# J7AEP_GPU_BXS464_WRAP0_GPU_SS_0_CORE_MMRS register map
Vendor: Texas Instruments
Registers are 64-bit, access per field, reset 0x0 unless marked. A register's access mark holds for its fields unless they carry their own. Offsets are as the file gives them; [hi:lo] are bit positions; 'fields as' and 'values as' point back to an identical list.

## J7AEP_GPU_BXS464_WRAP0_GPU_SS_0_CORE_MMRS (part 2 of 5)
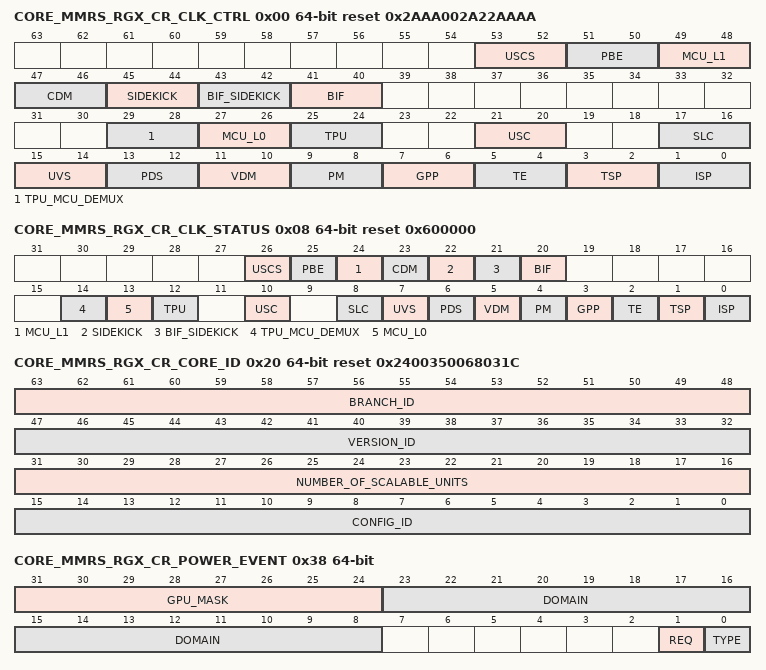
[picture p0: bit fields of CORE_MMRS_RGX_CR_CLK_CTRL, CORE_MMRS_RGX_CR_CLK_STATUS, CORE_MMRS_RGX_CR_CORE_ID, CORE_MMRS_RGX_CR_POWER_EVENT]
0x00 CORE_MMRS_RGX_CR_CLK_CTRL reset 0x2AAA002A22AAAA — Core Module Clock Control Modes. Allows individual domain clocks to be forced off, forced on or operate under automatic pipeline activity based clock gating. This register is generally controlled by the GPU firmware and should be set to AUTO. Clock gating reduces the power consumed by the device.
  [53:52] USCS rw, [51:50] PBE rw, [49:48] MCU_L1 rw, [47:46] CDM rw, [45:44] SIDEKICK rw, [43:42] BIF_SIDEKICK rw, [41:40] BIF rw, [29:28] TPU_MCU_DEMUX rw, [27:26] MCU_L0 rw, [25:24] TPU rw, [21:20] USC rw, [17:16] SLC rw, [15:14] UVS rw, [13:12] PDS rw, [11:10] VDM rw, [9:8] PM rw, [7:6] GPP rw, [5:4] TE rw, [3:2] TSP rw, [1:0] ISP rw
0x08 CORE_MMRS_RGX_CR_CLK_STATUS ro reset 0x600000 — Reports the current module clock status Clock gating state reflects the condition of the clock for each module
  [26] USCS, [25] PBE, [24] MCU_L1, [23] CDM, [22] SIDEKICK, [21] BIF_SIDEKICK, [20] BIF, [14] TPU_MCU_DEMUX, [13] MCU_L0, [12] TPU, [10] USC, [8] SLC, [7] UVS, [6] PDS, [5] VDM, [4] PM, [3] GPP, [2] TE, [1] TSP, [0] ISP
0x18 CORE_MMRS_RGX_CR_PRODUCT_ID ro reset 0x8470000 — Reports the product ID Product ID Register
  [31:16] IMG_PRODUCT_ID
0x20 CORE_MMRS_RGX_CR_CORE_ID ro reset 0x2400350068031C — Reports the product ID Core ID Register
  [63:48] BRANCH_ID — B - Branch ID
  [47:32] VERSION_ID — V - Version ID
  [31:16] NUMBER_OF_SCALABLE_UNITS — N - Number of scalable Units
  [15:0] CONFIG_ID — C - Config ID
0x28 CORE_MMRS_RGX_CR_CORE_IP_INTEGRATOR_ID ro — Reports the product ID Core IP Integrator ID Register
  [31:0] VALUE — IP company ID/Designer
0x30 CORE_MMRS_RGX_CR_CORE_IP_CHANGELIST ro — Reports the version control ID Core IP Changelist Register
  [31:0] VALUE — Version control ID
0x38 CORE_MMRS_RGX_CR_POWER_EVENT — Allows the firmware to request a power-up or power-down operation to an external (to Rogue) power-management controller When the power event operation is accepted, the firmware will either receive an RGX_CR_EVENT_STATUS_POWER_COMPLETE or RGX_CR_EVENT_STATUS_POWER_ABORT. On receipt of the reponse it will de-assert the request before issuing another request.
  [31:24] GPU_MASK rw — One bit per GPU indicating which GPUs are considered for the power event.
  [23:8] DOMAIN rw — sets which power island is enabled for the current power event request; bit0:jones, bit1-8:dusts, bit9-12:blackpearls
  [1] REQ rw — Set when a power event operation is requested
  [0] TYPE rw — The requested power event operation
0x50 CORE_MMRS_RGX_CR_DUSTS_ENABLE ro reset 0xFF — Controls how many Dual Unified Shading and Texturing Units (DUSTs) are enabled. Each DUST Contain 2 USCs and a TPU module. (Available on 2. X.X.X cores and above). Only applicable in cores with a B.V.N.C > 2.0.0.0 Controls how many Dual Unified Shading and Texturing Units (DUSTs) are enabled. Each DUST Contain 2 USCs and TPU module. Each DUST Contains 2 USCs and a TPU module. Please refer to the Customer User Guide for valid combinations. The value of this register can be overridden by the dusts_enable port at the top level. 1: DustA enabled. 3: DustB enabled. 7: DustC enabled. 15: DustD enabled
  [7:0] ENABLE — Dusts enabled
0x58 CORE_MMRS_RGX_CR_DUSTS_FUSE ro reset 0xFF — Indicates how many of the available DUST modules are enabled on the Silicon. (Available on 2.X.X.X cores and above). Shows the raw value of dusts_enable port.
  [7:0] ENABLE — Dusts enabled
0x80 CORE_MMRS_RGX_CR_CLK_XTPLUS_CTRL reset 0x800000000 — Core Module Clock Control Modes. Allows individual domain clocks to be forced off, forced on or operate under automatic pipeline activity based clock gating. This register is generally controlled by the GPU firmware and should be set to AUTO. Clock gating reduces the power consumed by the device.
  [35:34] ASTC rw
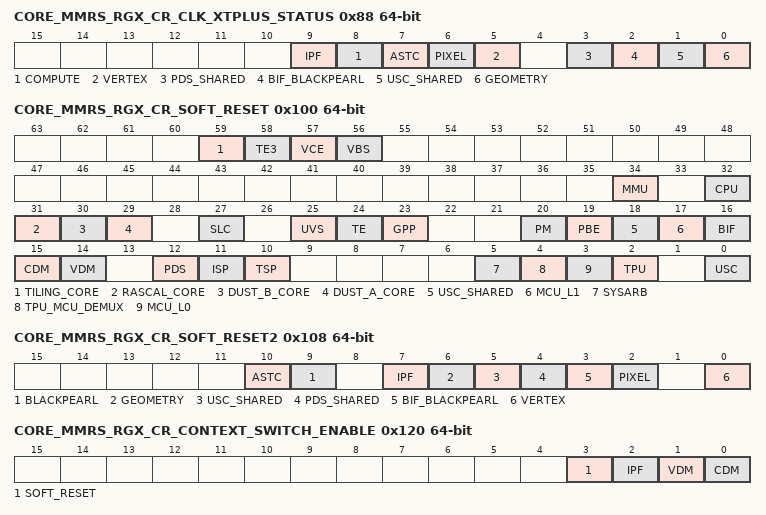
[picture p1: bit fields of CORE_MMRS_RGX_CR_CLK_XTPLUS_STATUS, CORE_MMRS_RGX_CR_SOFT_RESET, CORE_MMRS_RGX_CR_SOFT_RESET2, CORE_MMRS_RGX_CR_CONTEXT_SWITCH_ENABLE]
0x88 CORE_MMRS_RGX_CR_CLK_XTPLUS_STATUS ro — Reports the current module clock status Clock gating state reflects the condition of the clock for each module
  [9] IPF, [8] COMPUTE, [7] ASTC, [6] PIXEL, [5] VERTEX, [3] PDS_SHARED, [2] BIF_BLACKPEARL, [1] USC_SHARED, [0] GEOMETRY
0xE0 CORE_MMRS_RGX_CR_SOC_TIMER_GRAY ro — This register contains the value of a 64-bit external gray coded timer. (Available on 2.X.X.X cores and above).
  [63:0] VALUE
0xE8 CORE_MMRS_RGX_CR_SOC_TIMER_BINARY ro — This register contains the value of a 64-bit external binary coded timer.
  [63:0] VALUE
0x100 CORE_MMRS_RGX_CR_SOFT_RESET — Core soft reset control register. Write a '1' to reset and a '0' to clear See the soft reset section in the TRM to understand how to use the soft reset register.
  [59] TILING_CORE ro
  [58] TE3 ro
  [57] VCE ro
  [56] VBS ro
  [34] MMU rw
  [32] CPU rw — Includes MTS and META or MIPS
  [31] RASCAL_CORE rw — Note that the RASL_CORE bit affects logic related to the reading and writing of registers. This soft reset should therefore be used with caution. Upon power down events it is necessary to reset every register, so this bit should be used, but it must be release before any other resets, or beofre anyu other registers are programmed
  [30] DUST_B_CORE rw
  [29] DUST_A_CORE rw
  [27] SLC rw
  [25] UVS rw
  [24] TE rw
  [23] GPP rw
  [20] PM rw
  [19] PBE rw
  [18] USC_SHARED rw
  [17] MCU_L1 rw
  [16] BIF rw — Bifpmcache BIF
  [15] CDM rw
  [14] VDM rw
  [12] PDS rw
  [11] ISP rw
  [10] TSP rw
  [5] SYSARB rw
  [4] TPU_MCU_DEMUX rw
  [3] MCU_L0 rw
  [2] TPU rw
  [0] USC rw
0x108 CORE_MMRS_RGX_CR_SOFT_RESET2 — Core soft reset control register. Write a '1' to reset and a '0' to clear See the soft reset section in the TRM to understand how to use the soft reset register.
  [10] ASTC rw, [9] BLACKPEARL ro, [7] IPF ro, [6] GEOMETRY ro, [5] USC_SHARED ro, [4] PDS_SHARED ro, [3] BIF_BLACKPEARL ro, [2] PIXEL ro, [0] VERTEX ro
0x120 CORE_MMRS_RGX_CR_CONTEXT_SWITCH_ENABLE — The use of the this register has been deprecated.
  [3] SOFT_RESET rw, [2] IPF rw, [1] VDM rw, [0] CDM rw
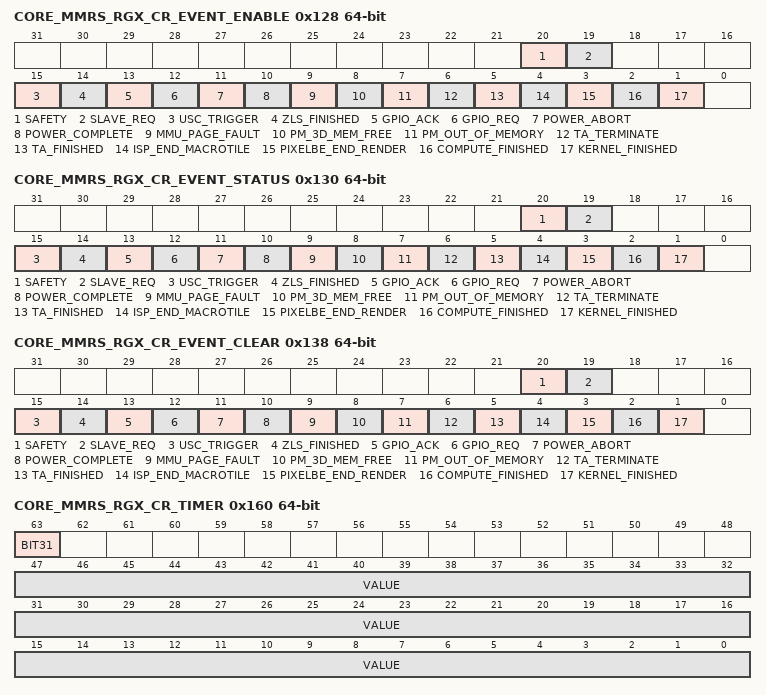
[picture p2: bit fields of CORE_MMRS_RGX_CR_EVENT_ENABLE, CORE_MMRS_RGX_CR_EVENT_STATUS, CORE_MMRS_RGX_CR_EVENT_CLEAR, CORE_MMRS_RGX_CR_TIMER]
0x128 CORE_MMRS_RGX_CR_EVENT_ENABLE — This register is used to enable GPU interrupts directly to the host Writing a '1' to a bit field enables the relevant event This register should only be programmed when the META firmware is not used If the META firmware is used, the GPU interrupt enables must be programmed in RGX_CR_DMn_INTERRUPT_ENABLE instead
  [20] SAFETY rw — Indicates an interrupt event from an active safety feature has been received
  [19] SLAVE_REQ rw — Indicates an interrupt event from a slave has been received.
  [15] USC_TRIGGER rw — One or more USC has executed a nop.trigger instruction
  [14] ZLS_FINISHED rw — ZLS has finished all tiles in a Render
  [13] GPIO_ACK rw — General Purpose ouput acknowledgement
  [12] GPIO_REQ rw — General Purpose input request
  [11] POWER_ABORT rw — The requested power operation has been denied.
  [10] POWER_COMPLETE rw — The requested power operation has completed
  [9] MMU_PAGE_FAULT rw — An MMU page fault has occurred
  [8] PM_3D_MEM_FREE rw — PM memory allocation completed for the current render
  [7] PM_OUT_OF_MEMORY rw — PM memory allocation failed for a macro-tile
  [6] TA_TERMINATE rw — The TE has aborted a macro tile after a failted PM allocation request
  [5] TA_FINISHED rw — The TA phase has completed
  [4] ISP_END_MACROTILE rw — ISP End-of-Macrotile
  [3] PIXELBE_END_RENDER rw — The 3D phase has completed
  [2] COMPUTE_FINISHED rw — The compute phase has completed
  [1] KERNEL_FINISHED rw — A compute kernel has completed and updated the associated event object in external memory
0x130 CORE_MMRS_RGX_CR_EVENT_STATUS — The event status register indicate the source of an interrupt generated by PowerVR RGX These events only schedule an interrupt context thread to run on META when the appropriate enables are set in RGX_CR_DMn_INTERRUPT_ENABLE
  fields as CORE_MMRS_RGX_CR_EVENT_ENABLE
0x138 CORE_MMRS_RGX_CR_EVENT_CLEAR — This register is used to clear event interrupts. Writing a '1' to a bit field clears the relevant event.
  [20] SAFETY wo — Indicates an interrupt event from an active safety feature has been received
  [19] SLAVE_REQ wo — Indicates an interrupt event from a slave has been received.
  [15] USC_TRIGGER wo — One or more USC has executed a nop.trigger instruction
  [14] ZLS_FINISHED wo — ZLS has finished all tiles in a Render
  [13] GPIO_ACK wo — General Purpose ouput acknowledgement
  [12] GPIO_REQ wo — General Purpose input request
  [11] POWER_ABORT wo — The requested power operation has been denied.
  [10] POWER_COMPLETE wo — The requested power operation has completed
  [9] MMU_PAGE_FAULT wo — An MMU page fault has occurred
  [8] PM_3D_MEM_FREE wo — PM memory allocation completed for the current render
  [7] PM_OUT_OF_MEMORY wo — PM memory allocation failed for a macro-tile
  [6] TA_TERMINATE wo — The TE has aborted a macro tile after a failted PM allocation request
  [5] TA_FINISHED wo — The TA phase has completed
  [4] ISP_END_MACROTILE wo — ISP End-of-Macrotile
  [3] PIXELBE_END_RENDER wo — The 3D phase has completed
  [2] COMPUTE_FINISHED wo — The compute phase has completed
  [1] KERNEL_FINISHED wo — A compute kernel has completed and updated the associated event object in external memory
0x140 CORE_MMRS_RGX_CR_GPIO_OUTPUT_DATA — General Purpose Input/Output interface for implementing communication protocol between HW external to Rogue and the firmware These registers are connected to top-level pins These registers are driven by the firmware. When the request is accepted (by HW external to Rogue), an interrupt will be raised via RGX_CR_EVENT_STATUS_GPIO_ACK The purpose and use of these registers depends upon the system implementation.
  [7:0] DATA rw — The data the firmware wants to transfer
0x148 CORE_MMRS_RGX_CR_GPIO_OUTPUT_REQ — General Purpose Input/Output interface for implementing communication protocol between HW external to Rogue and the firmware This register is connected to a top-level pin This register is driven by the firmware. When the request is accepted (by HW external to Rogue), an interrupt will be raised via RGX_CR_EVENT_STATUS_GPIO_ACK This signal is set to indicate output data is ready to be sampled. The purpose and use of these registers depends upon the system implementation.
  [0] REQ rw — Set when the firmware wants to communicate with a external HW
0x150 CORE_MMRS_RGX_CR_GPIO_INPUT_DATA ro — General Purpose Input/Output interface for implementing communication protocol between HW external to Rogue and the firmware This register is connected to top-level pins This register is driven by HW external to rogue before raising an RGX_CR_EVENT_STATUS_GPIO_ACK event The purpose and use of these registers depends upon the system implementation.
  [7:0] DATA — The incoming data from HW external to Rogue
0x158 CORE_MMRS_RGX_CR_GPIO_INPUT_ACK — General Purpose Input/Output interface for implementing communication protocol between HW external to Rogue and the firmware This register is connected to a top-level pin This register is driven by external HW in response to an RGX_CR_EVENT_STATUS_GPIO_REQ event. Setting this signal completes the transaction. Once the data (input data) has been sampled the REQ signal should be de-asserted by the firmware. The ACK signal should be de-assert by external hard in reposnse. Once this is complete the firmware can commence the next transaction. The purpose and use of these registers depends upon the system implementation.
  [0] ACK rw — Set by the firmware when it has acknowledged the incoming request
0x160 CORE_MMRS_RGX_CR_TIMER ro — This register contains the value of a 48-bit internal timer. The timer runs continuously, and wraps at the top end. It counts 256 cycles at the core clock frequency. This means that at 100 MHz: 1 count value = 1/100MHz = 256 * 10 * 10^-9 seconds = 2. 56 us In order to avoid having to issue three 32-bit reads to detect the lower 32-bits wrapping, the MSB of the low 32-bit word is duplicated in the MSB of the high 32-bit word.
  [63] BIT31, [47:0] VALUE
0x168 CORE_MMRS_RGX_CR_AXI_EXACCESS — AXI exclusive access enable register
  [0] SOCIF_ENABLE rw — enable the exclusive access logic in the socif img_axi2img. vhd module
0x190 CORE_MMRS_RGX_CR_PM_TASK_MLIST_LOAD — This register is part of the parameter management, which controls the allocation and de-allocation of memory for the 3D display list (parameters). The MLIST is the list of Pages which have been allocated to thew MMU, to map ALIST pages into the parameter manmagement physical memory. It is controlled by IMGs Services and Firmware. This register triggers the loading of the pointer to this list. Note that as this list sits in it's own virtual address space it is effectively a count of the pages currently allocated to the render target for mapping the pages from a virtual to physical address space.
  [0] PENDING wo — A write to this register will cause the MLIST pointer to be loaded from either PM_MLIST0_START_OF or PM_MLIST1_START_OF, depending upon the Context ID contained in PM_CONTEXT_ID_MLS_LS. A read to this register return '1' until this operation has completed.
0x198 CORE_MMRS_RGX_CR_PM_TASK_MLIST_CLEAR — This register is part of the parameter management, which controls the allocation and de-allocation of memory for the 3D display list (parameters). The MLIST is the list of Pages which have been allocated to thew MMU, to map ALIST pages into the parameter manmagement physical memory. It is controlled by IMGs Services and Firmware. This register triggers resets the pointer to the MLIST to 0.
  [0] PENDING wo — A write to this register will cause the MLIST pointer to be reset to 0. A read to this register return '1' until this operation has completed.
0x1A0 CORE_MMRS_RGX_CR_PM_TA_MAX_RENDER_TARGET — This register is deprecated and has no function.
  [10:0] ID rw — If used, the software should program this with the maximum render target array index used within the Scene
0x1A8 CORE_MMRS_RGX_CR_PM_MTILE_ARRAY_REORDER_VALID_STATUS ro — This register is deprecated and has no function.
  [0] OP
0x1B0 CORE_MMRS_RGX_CR_PM_EMPTY_PAGE_FAST_FREEING reset 0x1 — This register is part of the parameter management, which controls the allocation and de-allocation of memory for the 3D display list (parameters). This register enables an optimisation which causes pages which have been allocated during the TA phase to store display list data, but have had no data written to them to be freed at the end of the TA kick. When disabled these pages would not be freed until the render is in progress.
  [0] ID rw — When set, enable freeing of unused pages during TA phase
0x1B8 CORE_MMRS_RGX_CR_PM_MMU_REMAP_PENDING — This register is part of the parameter management, which controls the allocation and de-allocation of memory for the 3D display list (parameters). This register starts the process of remapping the remaining physical pages at the end render back into the 2 TA display list virtual address spaces. This operation must be performed at the end of a partial render. The opration is trigger by a write to this register, and is complete when a read to this register returns '0'. Once this operation is complete the TA can be restarted.
  [0] OP wo — Pending status register corresponding to the MMU remapping operation, it will become '1' when written and deassert when the operation complete.
0x1C0 CORE_MMRS_RGX_CR_PM_PBE_FORCE_FREEING reset 0x1 — This register is part of the parameter management, which controls the allocation and de-allocation of memory for the 3D display list (parameters). Normally freeing of memory is associated with macrotiles (a portion of the screen) and is performed when macrotile(s) have been rendered. When this register is set it will force freeing of all memory irrespective of the macrotile status, on the end of the render. Where all macrotiles are being rendered this register will have no affect.
  [0] ENABLE rw — When this bit is set, PM will free all the 3D context Memory when a genuine pixelbe end of render is received.
0x1C8 CORE_MMRS_RGX_CR_PM_PDS_STARTOF_MTILEFREE
  [16:0] OP rw — This startof register indicates the macrotile number of the PDSs current macrotile free request, needs to be programmed by FW on a render start
0x200 CORE_MMRS_RGX_CR_PM_TASK_3D_FREE_LOAD
  [0] PENDING wo — A write into this register will cause the 3D free list context to be loaded from the relevant configuration registers
0x208 CORE_MMRS_RGX_CR_PM_TASK_TA_FREE_LOAD
  [0] PENDING wo — A write into this register will cause the TA free list context to be loaded from the relevant configuration registers
0x210 CORE_MMRS_RGX_CR_PM_TA_FSTACK_BASE — Effective on load TA context, this register defines the base address of the free list stack being referenced during TA processing.
  [39:4] ADDR rw — 1TB Addressable, 128 bits aligned Base Address for TA context page tables in the DPM module
0x218 CORE_MMRS_RGX_CR_PM_3D_FSTACK_BASE — Effective on load 3D context, this register defines the base address of the free list table being referenced in the process of de-allocating pages during a 3D render.
  [39:4] ADDR rw — 1TB Addressable, 128 bits aligned Base Address for 3D context page tables in the DPM module
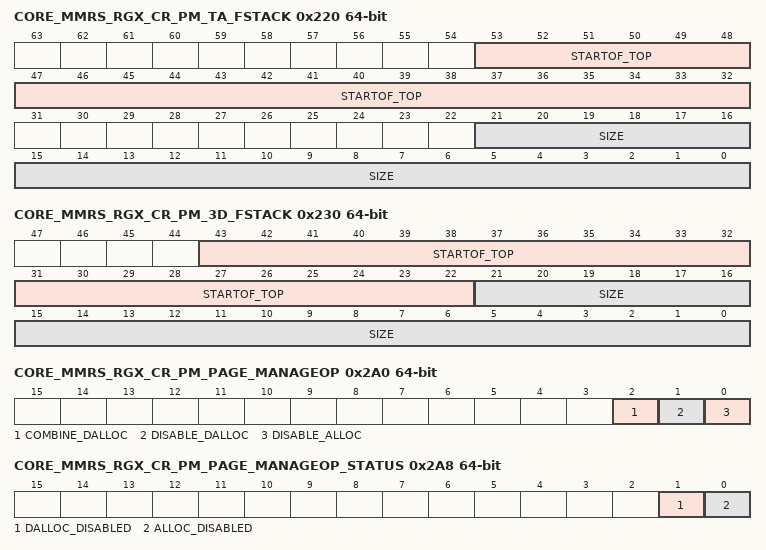
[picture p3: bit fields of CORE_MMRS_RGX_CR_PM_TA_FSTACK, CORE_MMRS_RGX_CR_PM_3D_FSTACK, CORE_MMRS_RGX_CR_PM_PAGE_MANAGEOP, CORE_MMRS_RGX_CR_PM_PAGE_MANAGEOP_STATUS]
0x220 CORE_MMRS_RGX_CR_PM_TA_FSTACK — Note: each 16GB 4KB addressable page (22 bits) is rounded to dword aligned
  [53:32] STARTOF_TOP rw — This register defines the head pointer of the free list in terms of 4K free pages in the free list stack, effective on a load TA context.
  [21:0] SIZE rw — This register defines the number of 4K pages in the free list stack used for the TA page allocation, effective on a load TA context.
0x230 CORE_MMRS_RGX_CR_PM_3D_FSTACK — Note: each 16GB 4KB addressable page (22 bits) is rounded to dword aligned
  [43:22] STARTOF_TOP rw — This register defines the head pointer of the free list in terms of 4K free pages in the free list stack, effective on a load TA context.
  [21:0] SIZE rw — This register defines the number of 4K pages in the free list stack used for the TA page allocation, effective on a load TA context.
0x240 CORE_MMRS_RGX_CR_PM_MTILE_ARRAY — Effective Immediately.
  [39:4] BASE_ADDR rw — 1TB Addressable, 128 bits aligned Base Address for Mtile Array Base
0x248 CORE_MMRS_RGX_CR_PM_VHEAP_TABLE — Effective immediately, this register defines the base address of the virtual heap table information. The size of the Virtual Heap needs to be no smaller than PM_VHEAP_TABLE_SIZE Dwords.
  [39:4] BASE_ADDR rw — 1TB Addressable, 128 bits aligned Base Address for Virtual Heap Table
0x250 CORE_MMRS_RGX_CR_PM_TASK_VHEAP_LOAD
  [0] PENDING rw — Causes the vheap to be loaded as specified by the relevant configuration registers, when it is done the hw will clear this bit
0x258 CORE_MMRS_RGX_CR_PM_TASK_VHEAP_CLEAR
  [0] PENDING rw — Causes the vheap to be cleared as specified by the relevant configuration registers. When it is done, the hw will clear this bit
0x260 CORE_MMRS_RGX_CR_PM_TASK_VHEAP_STORE
  [0] PENDING rw — Causes the vheap to be stored as specified by the relevant configuration registers. When it is done, the hw will clear this bit
0x268 CORE_MMRS_RGX_CR_PM_ALIST0_START_OF — start pointer of the allocation list tail,in size of 8 bytes
  [32:0] TAIL rw — allocation List 0 tail pointer
0x270 CORE_MMRS_RGX_CR_PM_ALIST0_STATUS ro — pointer of current allocation list,in size of 8 bytes
  [32:0] TAIL — allocation List tail pointer
0x278 CORE_MMRS_RGX_CR_PM_ALIST1_START_OF — start of the tail pointer of current allocation list,effecitve on an allocation_list_load
  [32:0] TAIL rw — start of the allocation list tail pointer
0x280 CORE_MMRS_RGX_CR_PM_ALIST1_STATUS ro — pointer of current allocation list,in size of 8 bytes
  [32:0] TAIL — allocation List tail pointer
0x288 CORE_MMRS_RGX_CR_PM_TASK_ALIST_LOAD
  [0] PENDING wo — the write to this register will cause allocation list to be loaded from the relevant configuration registers
0x290 CORE_MMRS_RGX_CR_PM_TASK_ALIST_CLEAR
  [0] PENDING wo — the write to this register will causes the allocation list to be cleard from the relevant configuration registers
0x298 CORE_MMRS_RGX_CR_PM_DEALLOCATION_STARTOF_MASK
  [15:0] OP rw — This is the start of the mask PM deallocation will be based on. Normally, it is 0. However, in ISP context resume or extra 3D timeout case, the driver has to programme the value from the previous render.
0x2A0 CORE_MMRS_RGX_CR_PM_PAGE_MANAGEOP
  [2] COMBINE_DALLOC rw — 1 means the PM writes to the free stack will be burst combined
  [1] DISABLE_DALLOC rw — 1 means the PM page management deallocation operation will be disabled
  [0] DISABLE_ALLOC rw — 1 means the PM page management allocation operation will be disabled
0x2A8 CORE_MMRS_RGX_CR_PM_PAGE_MANAGEOP_STATUS ro
  [1] DALLOC_DISABLED — 1 means the PM page management operation has been disabled
  [0] ALLOC_DISABLED — 1 means the PM page management operation has been disabled
0x2B0 CORE_MMRS_RGX_CR_PM_CONTEXT_PB_BASE
  [2:0] CMP rw — Defines whether the TA/3D/HOST contexts are using the same parameter buffer. Setting a bit to '1' indicates that the context is using a different parameter buffer. Bit 0 = 0 : Unified Free List 3D context Parameter buffer = Unified Free List TA context Parameter buffer Bit 1 = 0 : 3D context parameter buffer = TA context parameter buffer Bit 2 = 0 : MMU Free List 3D context Parameter buffer = MMU Free List TA context Parameter buffer[this is a per context resource, so it should be the same with bit 1
0x2B8 CORE_MMRS_RGX_CR_PM_MLIST0_START_OF — start value of the mlist tail @ the loading of the context, in size of 4 bytes, stride is 64KB
  [21:0] TAIL rw — allocation List 0 tail pointer
0x2C0 CORE_MMRS_RGX_CR_PM_MLIST0_STATUS ro — pointer of current mmu allocation list,in size of 4 bytes, stride is 64KB
  [21:0] TAIL — allocation List 1 tail pointer
0x2C8 CORE_MMRS_RGX_CR_PM_MLIST1_START_OF — start of the tail pointer of mmu allocation list,effecitve on an allocation_list_load
  [21:0] TAIL rw — start of the allocation list 1 tail pointer
0x2D0 CORE_MMRS_RGX_CR_PM_MLIST1_STATUS ro — pointer of mmu allocation list1 pointer,in size of 4 bytes
  [21:0] TAIL — mmu allocation List 1 tail pointer
0x2D8 CORE_MMRS_RGX_CR_PM_MLIST0_BASE — This register defines the base address of the mmu list 0 for the mmu pages, the stride has to be 64KBytes
  [39:4] ADDR rw — 1TB Addressable, 128 bits aligned Base Address for mmu list0 module, Effective Immediately
0x2E0 CORE_MMRS_RGX_CR_PM_MLIST1_BASE — This register defines the base address of the mmu list 1 for the mmu pages, the stride has to be a 64KBytes
  [39:4] ADDR rw — 1TB Addressable, 128 bits aligned Base Address for mmu list1 module, Effective Immediately
0x2F8 CORE_MMRS_RGX_CR_PM_VCE_VTOP_STATUS ro
  [20:0] OP — Virtual Page Pointer for the VCE, 8KB granularity
0x300 CORE_MMRS_RGX_CR_PM_TE_VTOP_STATUS ro
  [20:0] OP — Virtual Page Pointer for the TE, 8KB granularity
0x308 CORE_MMRS_RGX_CR_PM_OUTOF_MEM_SRC ro
  [2:0] OP — one hot encoding indicating which part of resource runs out of memory bit 0: normal ta free list, bit 1: unified ta free list, bit 2: mmu free list
0x310 CORE_MMRS_RGX_CR_PM_ALIST_VTOP_STATUS ro
  [20:0] OP — Virtual Page Pointer for the allocation list, 8KB granularity
0x318 CORE_MMRS_RGX_CR_PM_MMU_VTOP_STATUS ro
  [20:0] OP — Virtual Page Pointer for the MMU, 4KB granularity
0x320 CORE_MMRS_RGX_CR_PM_OUTOFMEM_ABORTALL
  [0] OP wo — Instruct the PM to Deny the TE allocation outstanding on Out Of Memory
0x328 CORE_MMRS_RGX_CR_PM_OUTOFMEM_RESTART
  [0] OP wo — Restart the PM after an Out of Memory and Abort sequence
0x330 CORE_MMRS_RGX_CR_PM_REQUESTING_SOURCE ro
  [1:0] OP — Requesting source when out of memory. Bit 1 : VCE, Bit 0 : TE
0x338 CORE_MMRS_RGX_CR_PM_PARTIAL_RENDER_ENABLE
  [0] OP rw — Partial Render Enable Bit
0x340 CORE_MMRS_RGX_CR_PM_3D_DEALLOCATE_SCANMODE
  [4:0] OP rw — This register defines the deallocation behaviour of the PM: value > 2 is only for debug, on ZLS mode 0, it can only set less than 2 0: PM will free the macrotile memory as soon as it is possible 1: PM only free one mtile for each traverse 2: PM only free two mtiles for each traverse ... 16: PM only free 16 mtiles for each traverse. Other Value are all invalid values
0x348 CORE_MMRS_RGX_CR_PM_TA_FSTACK_STATUS ro — Note: this is the pointer pointing to the TA free stack top. (4KB page pointer)
  [21:0] TOP — This status register indicated the ta context free list pointer status.
0x350 CORE_MMRS_RGX_CR_PM_3D_FSTACK_STATUS ro — Note: this is the pointer pointing to the 3D free stack top. (4KB page pointer)
  [21:0] TOP — This status register indicated the 3D context free list status
0x358 CORE_MMRS_RGX_CR_PM_RESERVE_PAGES reset 0x5
  [15:0] OP rw — This register defines the guard page required for one VCE/TE allocation. The requirement is set by the number of ppages needed to create the ALIST nodes when a vpage is closed. The MMU requirement is fixed at 3 ppages max for creatig a new ALIST mapping. The rest of the guarding is formed of the amount of ALIST space needed to form the maximum number of nodes a vpage could need. This is defined by the number of RTAs that could be present in a vpage. In all cores, the amount of ALIST space needed doesn't exceed 1 ppage. However the ALIST is allocated at vpage granularity so this needs to be rounded up to a vpage size in ppages. With a vpage size of 16KB or 4*4KB the requirement is 4 ppages and the TOTAL = 3+4 meaning a register setting of 0x7 is required. With a vpage size of 8KB or 2*4Kb the requirement is 2 ppages and the TOTAL = 3+2 meaning a register setting of 0x5 is required.
0x360 CORE_MMRS_RGX_CR_PM_DEALLOCATED_MASK_STATUS ro
  [15:0] TOP — This status register contains a bitmask of the macrotiles freed at this point in the render
0x368 CORE_MMRS_RGX_CR_PM_DEALLOCATING_MASK_STATUS ro
  [15:0] TOP — This status register indicates the mtile mask being freed at the current traverse
0x370 CORE_MMRS_RGX_CR_PM_PDS_MTILEFREE_STATUS ro
  [16:0] OP — This status register indicates the macrotile number of the PDSs current macrotile free request
0x378 CORE_MMRS_RGX_CR_PM_TA_FREE_CONTEXT
  [0] PENDING rw — free the ta context register operation
0x380 CORE_MMRS_RGX_CR_PM_3D_TIMEOUT_NOW
  [0] OP wo — free the 3D context
0x388 CORE_MMRS_RGX_CR_PM_3D_DEALLOCATE_ENABLE reset 0x1
  [0] OP rw — 3D deallocate enable mode
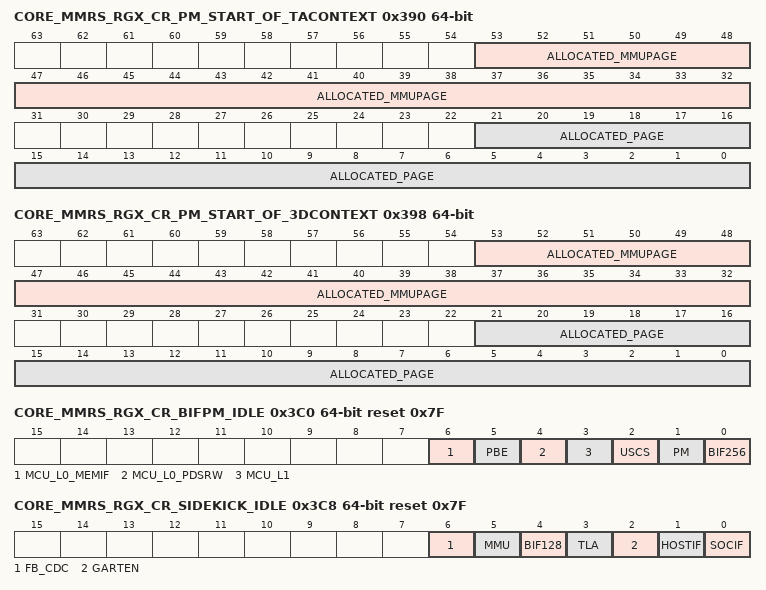
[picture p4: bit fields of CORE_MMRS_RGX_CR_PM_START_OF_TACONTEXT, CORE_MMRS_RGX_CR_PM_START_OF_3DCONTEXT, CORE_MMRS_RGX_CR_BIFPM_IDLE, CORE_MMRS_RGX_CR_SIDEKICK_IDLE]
0x390 CORE_MMRS_RGX_CR_PM_START_OF_TACONTEXT
  [53:32] ALLOCATED_MMUPAGE rw — Start of TA MMU pages[4KB] on loading of the TA context
  [21:0] ALLOCATED_PAGE rw — Start of TA pages[4KB] on loading of the TA context
0x398 CORE_MMRS_RGX_CR_PM_START_OF_3DCONTEXT
  [53:32] ALLOCATED_MMUPAGE rw — Start of 3D MMU pages[4KB] on loading of the TA context
  [21:0] ALLOCATED_PAGE rw — Start of 3D pages[4KB] on loading of the TA context
0x3A0 CORE_MMRS_RGX_CR_PM_TA_PAGE_STATUS ro
  [21:0] OP — The number of TA pages currently allocated
0x3A8 CORE_MMRS_RGX_CR_PM_3D_PAGE_STATUS ro
  [21:0] OP — The number of 3D pages currently allocated
0x3B0 CORE_MMRS_RGX_CR_PM_VCE_INFLIGHT_STATUS ro
  [20:0] OP — The Virtual Page Number in flight in the VCE Requestor
0x3B8 CORE_MMRS_RGX_CR_PM_TE_INFLIGHT_STATUS ro
  [20:0] OP — The Virtual Page Number in flight in the TE Requestor
0x3C0 CORE_MMRS_RGX_CR_BIFPM_IDLE ro reset 0x7F
  [6] MCU_L0_MEMIF — MCU L0 MEMIF Module IDLE
  [5] PBE — PBE Module IDLE
  [4] MCU_L0_PDSRW — MCU L0 PDSRW Module IDLE
  [3] MCU_L1 — MCU L1 Module IDLE
  [2] USCS — USC Shared Module IDLE
  [1] PM — PM Module IDLE
  [0] BIF256 — BIF256 Module IDLE
0x3C8 CORE_MMRS_RGX_CR_SIDEKICK_IDLE ro reset 0x7F
  [6] FB_CDC — FB CDC Module IDLE
  [5] MMU — MMU Module IDLE
  [4] BIF128 — BIF128 Module IDLE
  [3] TLA — TLA Module IDLE
  [2] GARTEN — GARTEN Module IDLE
  [1] HOSTIF — HOSTIF Module IDLE
  [0] SOCIF — SOCIF Module IDLE
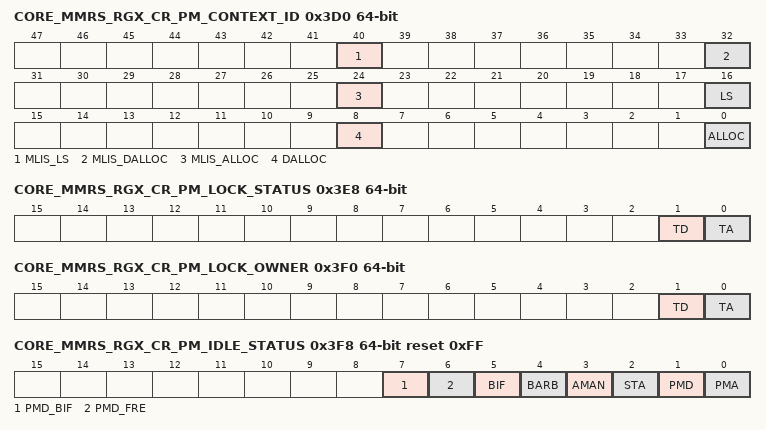
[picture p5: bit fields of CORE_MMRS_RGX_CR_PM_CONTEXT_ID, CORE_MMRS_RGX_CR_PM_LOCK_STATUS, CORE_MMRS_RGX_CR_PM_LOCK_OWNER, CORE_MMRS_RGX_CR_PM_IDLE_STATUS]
0x3D0 CORE_MMRS_RGX_CR_PM_CONTEXT_ID
  [40] MLIS_LS rw — MMU page List [TE,VCE aligned with this context ]Load Store Context ID
  [32] MLIS_DALLOC rw — MMU page List [TE,VCE aligned with this context ]DeAllocation Context ID
  [24] MLIS_ALLOC rw — MMU page List [TE,VCE aligned with this context ]Allocation Context ID
  [16] LS rw — Load Store Context ID for the allocation list
  [8] DALLOC rw — DeAllocation Context ID for the allocation list
  [0] ALLOC rw — Allocation Context ID for the allocation list
0x3D8 CORE_MMRS_RGX_CR_PM_3D_RENDER_TARGET_INDEX
  [10:0] ID rw — Render Target ID which is being rendered
0x3E0 CORE_MMRS_RGX_CR_PM_3D_RENDER_TARGET_LAST reset 0x1
  [0] ID rw — If this bit is set, this means the render will be the last one in the whole render target array. If no multiple render target array is present, this bit always needs set
0x3E8 CORE_MMRS_RGX_CR_PM_LOCK_STATUS ro
  [1] TD — Bit 1: 3D free list Lock Status. 0 idle/ 1 used
  [0] TA — Bit 0: TA free list Lock Status. 0 idle/ 1 used.
0x3F0 CORE_MMRS_RGX_CR_PM_LOCK_OWNER ro
  [1] TD — Bit 1 :3D free list Lock owner. 0 PMA / 1 PMD
  [0] TA — Bit 0: TA free list Lock Owner. 0 PMA / 1 PMD.
0x3F8 CORE_MMRS_RGX_CR_PM_IDLE_STATUS ro reset 0xFF
  [7] PMD_BIF — Idle Status Register of the PMD module bif state machine
  [6] PMD_FRE — Idle Status Register of the PMD module master state machine
  [5] BIF — Idle Status Register of the BIF Interface, default
  [4] BARB — Idle Status Register of the BIF Arbiter state BAR
  [3] AMAN — Idle Status Register of the Alist state machine
  [2] STA — Idle Status Register of the Stack Manager Modul
  [1] PMD — Idle Status Register of the PMD module
  [0] PMA — Idle Status Register of the PMA module
0x400 CORE_MMRS_RGX_CR_VDM_START — A write of '1' to this register starts the Vertex Data Master (TA) Reading the control stream pointed to by VDM_CTRL_STREAM_BASE
  [0] PULSE wo — Start VDM
0x408 CORE_MMRS_RGX_CR_VDM_CTRL_STREAM_BASE — The base address of the Vertex Data Master's Input Parameter Control Stream in external memory
  [39:2] ADDR rw — 1TB range, 32-bit aligned base address
0x410 CORE_MMRS_RGX_CR_VDM_CTRL_STREAM_CURRENT ro — This status register reports the current position in the input parameter format of the data being processed. This is a debug register. This is NOT the fetch address presented to the BIF, which is reading ahead Since the VDM Control Stream format is a structured as DWords, this is a 32-bit aligned address
  [39:2] ADDR — 1TB range, 32-bit aligned address
0x418 CORE_MMRS_RGX_CR_VDM_CALL_STACK_POINTER — The pointer to the control stream call stack. The current pointer within the VDM's call stack in external memory. The call stack is used whenever a call is made to another control stream, to store the return address (location in current control stream). This register should be programmed before each TA which uses a call stack This register needs to be saved/restored for each context
  [39:3] ADDR rw — 1TB range, 64-bit aligned base address
0x420 CORE_MMRS_RGX_CR_VDM_BATCH — The Batch number is a index list block (draw call) ID which is passed through the GPU pipeline. This is helpful for debug and performance profiling. The starting batch number should be programmed before the first TA phase of every frame The VDM will increment it on every Index List Block across TA phases until reset This register needs to be saved/restored for each context
  [13:0] NUMBER rw
0x428 CORE_MMRS_RGX_CR_VDM_CONTEXT_STATE_BASE — The base address in external memory of the VDM's context state buffer. On a context store the VDM will store its state to this address, and reload it on a context resume. The size and format of the data written is defined in the LLS section of the TRM. This register must be programmed before initiating a context store by writing to VDM_CONTEXT_STORE_START_PULSE.
  [39:4] ADDR rw — 1TB range, 128-bit aligned base address
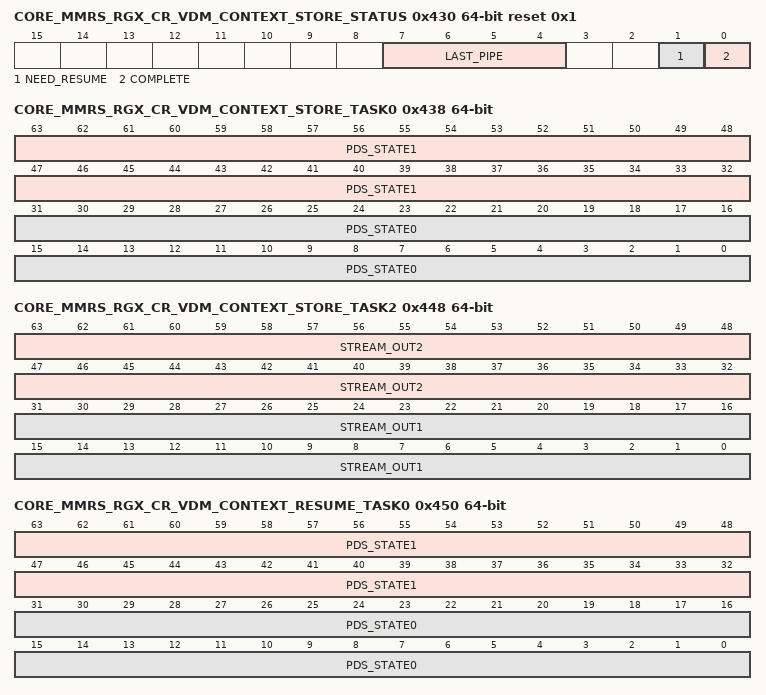
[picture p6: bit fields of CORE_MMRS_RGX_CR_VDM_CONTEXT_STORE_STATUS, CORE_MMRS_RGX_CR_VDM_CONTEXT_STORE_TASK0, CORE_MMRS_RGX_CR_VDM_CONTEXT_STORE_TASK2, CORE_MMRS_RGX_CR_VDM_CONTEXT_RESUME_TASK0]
0x430 CORE_MMRS_RGX_CR_VDM_CONTEXT_STORE_STATUS ro reset 0x1 — This register indicates the status of a VDM context switch operation. If a context store has been requested, then this muist be sample on TA finished. The firmware must wait for the COMPLETE bit to be set. The NEED_RESUME field will indicate whether the firmware needs to resume the TA. The LAST_PIPE field will indicate the TA pipe number from which to store context state if NEED_RESUME is set.
  [7:4] LAST_PIPE — The TA pipe number to which the VDM last sent indices
  [1] NEED_RESUME — The VDM still has control stream left to process, meaning this context must be resumed
  [0] COMPLETE — The VDM has completed the context store operation and fenced its state to external memory
0x438 CORE_MMRS_RGX_CR_VDM_CONTEXT_STORE_TASK0 rw — These words define the PDS State Update task which will be inserted into the VDM pipeline on a context store operation. The function of this task is described in the Rogue Context Switching Hardware Specification. Their format is defined in the Rogue Technical Reference Manual (TRM). This register must be programmed before writing to VDM_CONTEXT_STORE_START_PULSE.
  [63:32] PDS_STATE1, [31:0] PDS_STATE0
0x440 CORE_MMRS_RGX_CR_VDM_CONTEXT_STORE_TASK1 — This word defines the PDS State Update task which will be inserted into the VDM pipeline on a context store operation. The function of this task is described in the Rogue Context Switching Hardware Specification. Its format is defined in the Rogue Technical Reference Manual (TRM). This register must be programmed before writing to VDM_CONTEXT_STORE_START_PULSE.
  [31:0] PDS_STATE2 rw
0x448 CORE_MMRS_RGX_CR_VDM_CONTEXT_STORE_TASK2 rw — These words defines the Stream Out Sync program which will be inserted into the VDM pipeline as a PPP State Update on a context store operation. The function of this task is described in the Rogue Context Switching Hardware Specification. Its format is defined in the Rogue Technical Reference Manual (TRM). This register must be programmed before writing to VDM_CONTEXT_STORE_START_PULSE.
  [63:32] STREAM_OUT2, [31:0] STREAM_OUT1
0x450 CORE_MMRS_RGX_CR_VDM_CONTEXT_RESUME_TASK0 rw — These words define the PDS State Update task which will be written by the VDM to its context resume control stream on a context store operation. The function of this task is described in the Rogue Context Switching Hardware Specifiction. Their format is defined in the Rogue Technical Reference Manual (TRM). This register must be programmed before writing to VDM_CONTEXT_STORE_START_PULSE.
  [63:32] PDS_STATE1, [31:0] PDS_STATE0
0x458 CORE_MMRS_RGX_CR_VDM_CONTEXT_RESUME_TASK1 — This word defines the PDS State Update task which will be written by the VDM to its context resume control stream on a context store operation. The function of this task is described in the Rogue Context Switching Hardware Specifiction. Its format is defined in the Rogue Technical Reference Manual (TRM). This register must be programmed before writing to VDM_CONTEXT_STORE_START_PULSE.
  [31:0] PDS_STATE2 rw
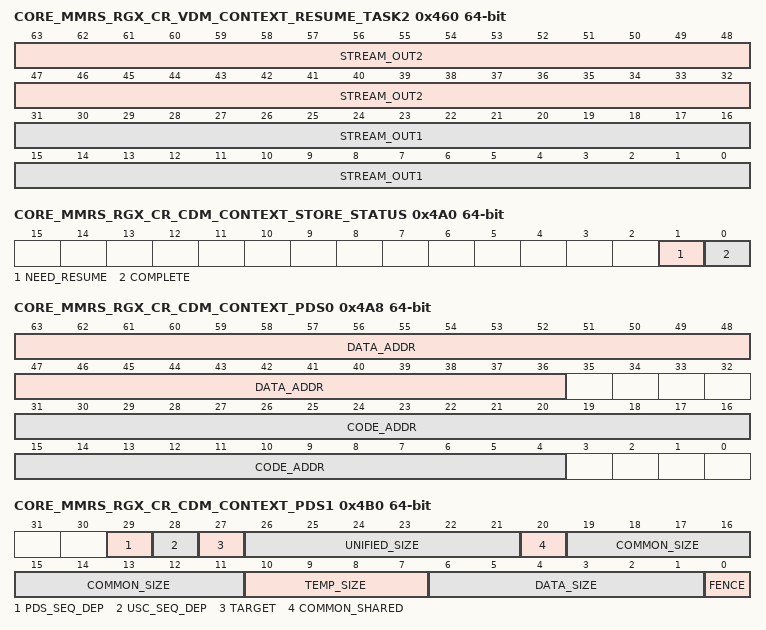
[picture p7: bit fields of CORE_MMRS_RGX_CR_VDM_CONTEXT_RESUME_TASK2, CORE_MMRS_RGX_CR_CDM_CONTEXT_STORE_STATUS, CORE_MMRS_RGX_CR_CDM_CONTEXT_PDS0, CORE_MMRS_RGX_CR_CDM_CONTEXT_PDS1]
0x460 CORE_MMRS_RGX_CR_VDM_CONTEXT_RESUME_TASK2 rw — These words defines the Stream Out Sync program which will be written, as a PPP State Update, by the VDM to its context resume control stream on a context store operation The function of this task is described in the Rogue Context Switching Hardware Specifiction Its format is defined in the Rogue Technical Reference Manual (TRM). This register must be programmed before writing to VDM_CONTEXT_STORE_START_PULSE.
  [63:32] STREAM_OUT2, [31:0] STREAM_OUT1
0x468 CORE_MMRS_RGX_CR_VDM_CONTEXT_STORE_START — Writing '1' to this register starts the VDM context store operation. The function of this task is described in the Rogue Context Switching Hardware Specifiction
  [0] PULSE wo
0x470 CORE_MMRS_RGX_CR_VDM_SYNC_PDS_DATA_BASE — The base address of the PDS data segment base for all TA state sync program 4GB range, 128-bit granularity The data segment size is always 256 bits The PDS code address for the TA state sync program is always 256 bits on from the data base address
  [31:4] ADDR rw
0x478 CORE_MMRS_RGX_CR_CDM_START — A write of '1' to this register starts the Compute Data Master reading it's control stream from memory.
  [0] PULSE wo — Start CDM
0x480 CORE_MMRS_RGX_CR_CDM_CTRL_STREAM_BASE — The base address of the Compute Data Master's Input Parameter Control Stream in external memory
  [39:2] ADDR rw — 1TB range, 32-bit aligned base address
0x488 CORE_MMRS_RGX_CR_CDM_CONTEXT_STORE — Writing '1' to this register starts the CDM context store operation.
  [0] PULSE wo
0x490 CORE_MMRS_RGX_CR_CDM_CONTEXT_LOAD — The firmware writes a '1' to this register starts the CDM context load operation. The CDM will set this register to '0' when the context load operation is complete The firmware should poll on this register after writing to it
  [0] PENDING wo
0x498 CORE_MMRS_RGX_CR_CDM_CONTEXT_STATE_BASE — The base address in external memory of the CDM's context state buffer, to which it will store its snapshot state on a context store and from which it will reload on a context resume
  [39:4] ADDR rw — 1TB range, 128-bit aligned base address
0x4A0 CORE_MMRS_RGX_CR_CDM_CONTEXT_STORE_STATUS ro — This register indicates the status of a CDM context switch operation. If a context store is in progress, this register must be sampled on a context store compute finished event. The firmware must wait for the COMPLETE bit to be set. The NEED_RESUME field will indicate whether the firmware needs to resume the compute phase.
  [1] NEED_RESUME — The CDM still has control stream left to process, meaning this context must be resumed
  [0] COMPLETE — The CDM has completed the context store operation and fenced its state to external memory
0x4A8 CORE_MMRS_RGX_CR_CDM_CONTEXT_PDS0 — This register contains the PDS Code and Data Addresses for the Store/Load Program. This program is sent to PDS on Context Store and Context Load.
  [63:36] DATA_ADDR rw — PDS Data Address for Store/Load Program, 128-bit aligned
  [31:4] CODE_ADDR rw — PDS Code Address for Store/Load Program, 128-bit aligned
0x4B0 CORE_MMRS_RGX_CR_CDM_CONTEXT_PDS1 — This register contains the PDS Task Data necessary to produce the Store/Load PDS Program Task from CDM to PDS
  [29] PDS_SEQ_DEP rw — PDS Sequential Dependency
  [28] USC_SEQ_DEP rw — USC Sequential Dependency
  [27] TARGET rw — USC Target [0=All, 1=Any]
  [26:21] UNIFIED_SIZE rw
  [20] COMMON_SHARED rw — PDS Common Store Allocation is Shared Registers
  [19:11] COMMON_SIZE rw — PDS Common Size
  [10:7] TEMP_SIZE rw — PDS Temp Size
  [6:1] DATA_SIZE rw — PDS Data Size
  [0] FENCE rw — Fence the Task in the PDS/USC - Set on Store, unset on Load
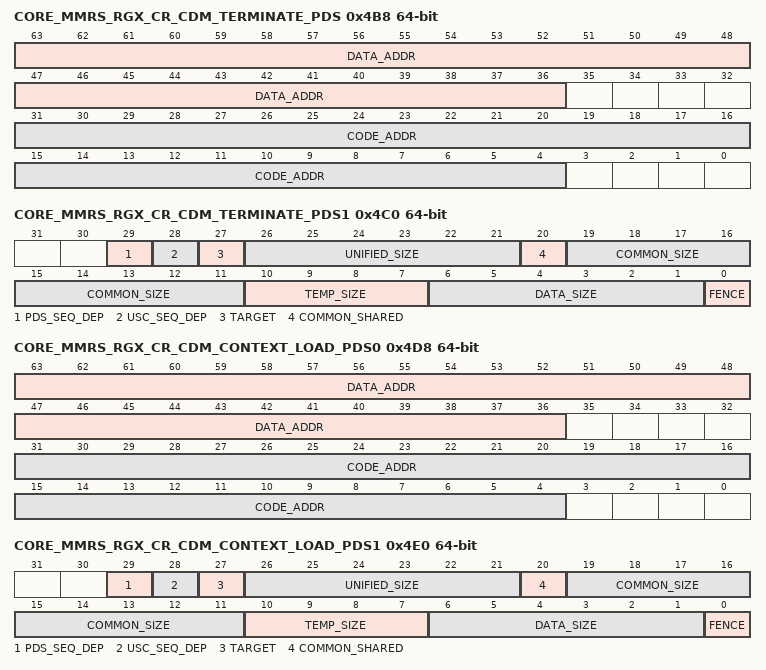
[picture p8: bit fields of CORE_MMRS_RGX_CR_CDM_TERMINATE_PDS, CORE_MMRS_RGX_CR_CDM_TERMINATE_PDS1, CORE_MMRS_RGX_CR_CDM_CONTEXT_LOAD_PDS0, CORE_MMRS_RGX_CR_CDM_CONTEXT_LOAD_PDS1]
0x4B8 CORE_MMRS_RGX_CR_CDM_TERMINATE_PDS — This register contains the PDS Code and Data Addresses for the Terminate Program. This program is sent to PDS on Context Store after the Context Store Program
  [63:36] DATA_ADDR rw — PDS Data Address for Terminate Program, 128-bit aligned
  [31:4] CODE_ADDR rw — PDS Code Address for Terminate Program, 128-bit aligned
0x4C0 CORE_MMRS_RGX_CR_CDM_TERMINATE_PDS1 — This register contains the PDS Task Data necessary to produce the Context Store Terminate PDS Program Task from CDM to PDS
  [29] PDS_SEQ_DEP rw — PDS Sequential Dependency
  [28] USC_SEQ_DEP rw — USC Sequential Dependency
  [27] TARGET rw — USC Target [0=All, 1=Any]
  [26:21] UNIFIED_SIZE rw
  [20] COMMON_SHARED rw — PDS Common Store Allocation is Shared Registers
  [19:11] COMMON_SIZE rw — PDS Common Size
  [10:7] TEMP_SIZE rw — PDS Temp Size
  [6:1] DATA_SIZE rw — PDS Data Size
  [0] FENCE rw — Fence the Task in the PDS/USC - Set on Store Terminate
0x4D8 CORE_MMRS_RGX_CR_CDM_CONTEXT_LOAD_PDS0 — This register contains the PDS Code and Data Addresses for the Store/Load Program. This program is sent to PDS on Context Store and Context Load.
  fields as CORE_MMRS_RGX_CR_CDM_CONTEXT_PDS0
0x4E0 CORE_MMRS_RGX_CR_CDM_CONTEXT_LOAD_PDS1 — This register contains the PDS Task Data necessary to produce the Store/Load PDS Program Task from CDM to PDS
  fields as CORE_MMRS_RGX_CR_CDM_CONTEXT_PDS1
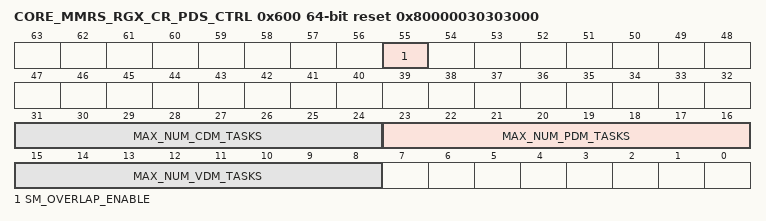
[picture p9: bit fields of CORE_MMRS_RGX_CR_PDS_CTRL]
0x600 CORE_MMRS_RGX_CR_PDS_CTRL reset 0x80000030303000 — Controls the maximum number of tasks per data master (per USC). There are a maximum of 48 tasks in the system
  [55] SM_OVERLAP_ENABLE rw — Enable per Data Master slot tracking within the PDS Slot Manager [SM] for improved performance while running overlapped
  [31:24] MAX_NUM_CDM_TASKS rw — The maximum number of compute tasks allowed on each USC, range 0 to 48
  [23:16] MAX_NUM_PDM_TASKS rw — The maximum number of pixel tasks allowed on each USC, range 0 to 48
  [15:8] MAX_NUM_VDM_TASKS rw — The maximum number of vertex tasks [VS, HS, GS when Tess not enabled] allowed on each USC, range 0 to 39 [Note reduced range to prevent Pixel/VDM system deadlock]
